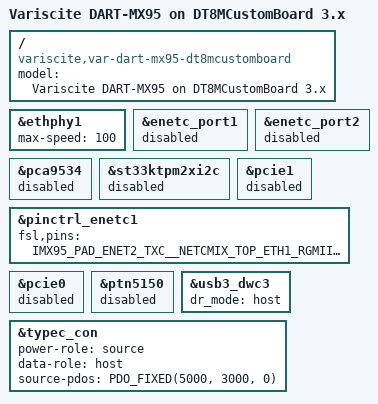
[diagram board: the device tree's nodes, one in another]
// SPDX-License-Identifier: (GPL-2.0+ OR MIT)
/*
 * Copyright 2023 NXP
 * Copyright 2024-2025 Variscite Ltd.
 */

#include "imx95-var-dart-sonata.dts"

/ {
	model = "Variscite DART-MX95 on DT8MCustomBoard 3.x";
	compatible = "variscite,var-dart-mx95-dt8mcustomboard",
		     "variscite,var-dart-mx95",
		     "fsl,imx95";
};

&ethphy1 {
	max-speed = <100>;
};

&enetc_port1 {
	status = "disabled";
};

&enetc_port2 {
	status = "disabled";
};

&pca9534 {
	status = "disabled";
};

&st33ktpm2xi2c {
	status = "disabled";
};

&pcie1 {
	status = "disabled";
};

&pinctrl_enetc1 {
	fsl,pins = <
		IMX95_PAD_ENET2_TXC__NETCMIX_TOP_ETH1_RGMII_TX_CLK		0x57e
		IMX95_PAD_ENET2_TX_CTL__NETCMIX_TOP_ETH1_RGMII_TX_CTL		0x57e
		IMX95_PAD_ENET2_TD3__NETCMIX_TOP_ETH1_RGMII_TD3			0x57e
		IMX95_PAD_ENET2_TD2__NETCMIX_TOP_ETH1_RGMII_TD2			0x57e
		IMX95_PAD_ENET2_TD1__NETCMIX_TOP_ETH1_RGMII_TD1			0x57e
		IMX95_PAD_ENET2_TD0__NETCMIX_TOP_ETH1_RGMII_TD0			0x57e
		IMX95_PAD_ENET2_RXC__NETCMIX_TOP_ETH1_RGMII_RX_CLK		0x57e
		IMX95_PAD_ENET2_RX_CTL__NETCMIX_TOP_ETH1_RGMII_RX_CTL		0x57e
		IMX95_PAD_ENET2_RD0__NETCMIX_TOP_ETH1_RGMII_RD0			0x57e
		IMX95_PAD_ENET2_RD1__NETCMIX_TOP_ETH1_RGMII_RD1			0x57e
		IMX95_PAD_ENET2_RD2__NETCMIX_TOP_ETH1_RGMII_RD2			0x57e
		IMX95_PAD_ENET2_RD3__NETCMIX_TOP_ETH1_RGMII_RD3			0x57e
	>;
};


&pcie0 {
	status = "disabled";
};

&ptn5150 {
	status = "disabled";
};

&usb3_dwc3 {
	dr_mode = "host";
	/delete-property/ usb-role-switch;
	/delete-property/ role-switch-default-mode;
};

&typec_con {
	power-role = "source";
	data-role = "host";
	/delete-property/ try-power-role;
	/delete-property/ sink-pdos;
	/delete-property/ op-sink-microwatt;
	source-pdos = <PDO_FIXED(5000, 3000, 0)>;
};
